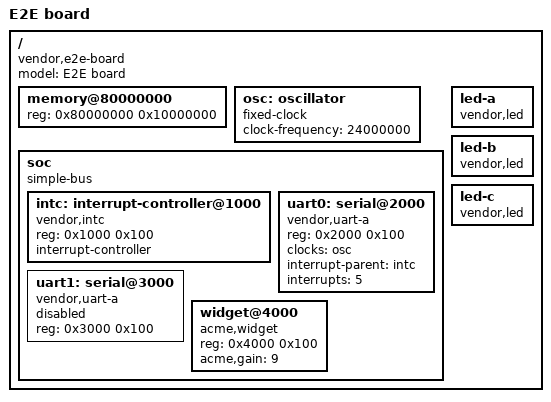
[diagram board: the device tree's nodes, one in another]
// The board the end-to-end suite starts from (US-4.5): a bus to open as a
// scope, a clock to reference, an interrupt controller, a disabled UART,
// memory for the address map, and loose nodes to arrange.
/dts-v1/;

/ {
	#address-cells = <1>;
	#size-cells = <1>;
	model = "E2E board";
	compatible = "vendor,e2e-board";

	memory@80000000 {
		device_type = "memory";
		reg = <0x80000000 0x10000000>;
	};

	osc: oscillator {
		compatible = "fixed-clock";
		#clock-cells = <0>;
		clock-frequency = <24000000>;
	};

	soc {
		compatible = "simple-bus";
		#address-cells = <1>;
		#size-cells = <1>;
		ranges;

		intc: interrupt-controller@1000 {
			compatible = "vendor,intc";
			reg = <0x1000 0x100>;
			interrupt-controller;
			#interrupt-cells = <1>;
		};

		uart0: serial@2000 {
			compatible = "vendor,uart-a";
			reg = <0x2000 0x100>;
			clocks = <&osc>;
			interrupt-parent = <&intc>;
			interrupts = <5>;
		};

		uart1: serial@3000 {
			compatible = "vendor,uart-a";
			reg = <0x3000 0x100>;
			status = "disabled";
		};

		widget@4000 {
			compatible = "acme,widget";
			reg = <0x4000 0x100>;
			acme,gain = <9>;
		};
	};

	led-a {
		compatible = "vendor,led";
	};

	led-b {
		compatible = "vendor,led";
	};

	led-c {
		compatible = "vendor,led";
	};
};
